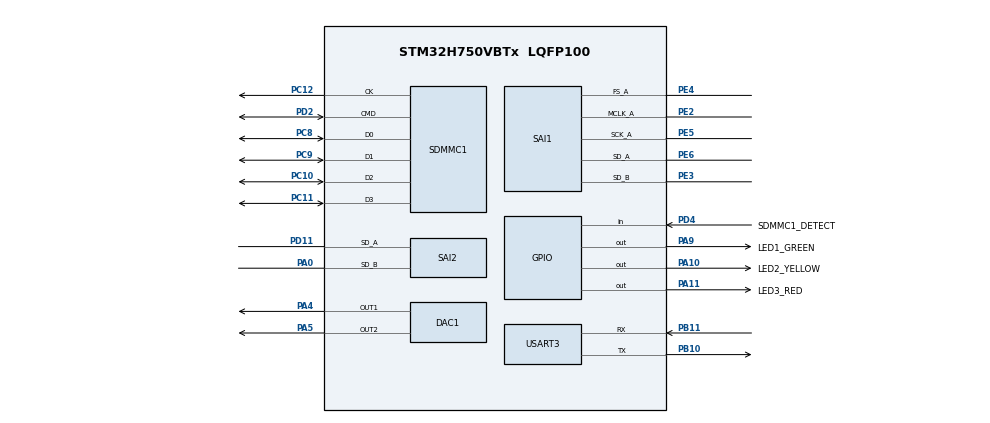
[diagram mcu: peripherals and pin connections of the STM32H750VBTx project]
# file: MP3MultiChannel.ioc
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CORTEX_M7.CPU_DCache=Enabled
CORTEX_M7.CPU_ICache=Enabled
DAC1.DAC1_OutputBuffer-DAC_OUT1=DAC_OUTPUTBUFFER_DISABLE
DAC1.DAC2_OutputBuffer-DAC_OUT2=DAC_OUTPUTBUFFER_DISABLE
DAC1.DAC_Channel-DAC_OUT1=DAC_CHANNEL_1
DAC1.DAC_Channel-DAC_OUT2=DAC_CHANNEL_2
DAC1.DAC_Trigger-DAC_OUT1=DAC_TRIGGER_T6_TRGO
DAC1.DAC_Trigger-DAC_OUT2=DAC_TRIGGER_T6_TRGO
Dma.DAC1_CH1.6.Direction=DMA_MEMORY_TO_PERIPH
Dma.DAC1_CH1.6.EventEnable=DISABLE
Dma.DAC1_CH1.6.FIFOMode=DMA_FIFOMODE_DISABLE
Dma.DAC1_CH1.6.Instance=DMA1_Stream6
Dma.DAC1_CH1.6.MemDataAlignment=DMA_MDATAALIGN_BYTE
Dma.DAC1_CH1.6.MemInc=DMA_MINC_ENABLE
Dma.DAC1_CH1.6.Mode=DMA_NORMAL
Dma.DAC1_CH1.6.PeriphDataAlignment=DMA_PDATAALIGN_BYTE
Dma.DAC1_CH1.6.PeriphInc=DMA_PINC_DISABLE
Dma.DAC1_CH1.6.Polarity=HAL_DMAMUX_REQ_GEN_RISING
Dma.DAC1_CH1.6.Priority=DMA_PRIORITY_LOW
Dma.DAC1_CH1.6.RequestNumber=1
Dma.DAC1_CH1.6.SignalID=NONE
Dma.DAC1_CH1.6.SyncEnable=DISABLE
Dma.DAC1_CH1.6.SyncPolarity=HAL_DMAMUX_SYNC_NO_EVENT
Dma.DAC1_CH1.6.SyncRequestNumber=1
Dma.DAC1_CH1.6.SyncSignalID=NONE
Dma.DAC1_CH2.7.Direction=DMA_MEMORY_TO_PERIPH
Dma.DAC1_CH2.7.EventEnable=DISABLE
Dma.DAC1_CH2.7.FIFOMode=DMA_FIFOMODE_DISABLE
Dma.DAC1_CH2.7.Instance=DMA1_Stream7
Dma.DAC1_CH2.7.MemDataAlignment=DMA_MDATAALIGN_BYTE
Dma.DAC1_CH2.7.MemInc=DMA_MINC_ENABLE
Dma.DAC1_CH2.7.Mode=DMA_NORMAL
Dma.DAC1_CH2.7.PeriphDataAlignment=DMA_PDATAALIGN_BYTE
Dma.DAC1_CH2.7.PeriphInc=DMA_PINC_DISABLE
Dma.DAC1_CH2.7.Polarity=HAL_DMAMUX_REQ_GEN_RISING
Dma.DAC1_CH2.7.Priority=DMA_PRIORITY_LOW
Dma.DAC1_CH2.7.RequestNumber=1
Dma.DAC1_CH2.7.SignalID=NONE
Dma.DAC1_CH2.7.SyncEnable=DISABLE
Dma.DAC1_CH2.7.SyncPolarity=HAL_DMAMUX_SYNC_NO_EVENT
Dma.DAC1_CH2.7.SyncRequestNumber=1
Dma.DAC1_CH2.7.SyncSignalID=NONE
Dma.Request0=SAI1_A
Dma.Request1=SAI1_B
Dma.Request2=SAI2_A
Dma.Request3=SAI2_B
Dma.Request4=USART3_RX
Dma.Request5=USART3_TX
Dma.Request6=DAC1_CH1
Dma.Request7=DAC1_CH2
Dma.SAI1_A.0.Direction=DMA_MEMORY_TO_PERIPH
Dma.SAI1_A.0.EventEnable=DISABLE
Dma.SAI1_A.0.FIFOMode=DMA_FIFOMODE_ENABLE
Dma.SAI1_A.0.FIFOThreshold=DMA_FIFO_THRESHOLD_FULL
Dma.SAI1_A.0.Instance=DMA1_Stream0
Dma.SAI1_A.0.MemBurst=DMA_MBURST_SINGLE
Dma.SAI1_A.0.MemDataAlignment=DMA_MDATAALIGN_HALFWORD
Dma.SAI1_A.0.MemInc=DMA_MINC_ENABLE
Dma.SAI1_A.0.Mode=DMA_CIRCULAR
Dma.SAI1_A.0.PeriphBurst=DMA_PBURST_SINGLE
Dma.SAI1_A.0.PeriphDataAlignment=DMA_PDATAALIGN_HALFWORD
Dma.SAI1_A.0.PeriphInc=DMA_PINC_DISABLE
Dma.SAI1_A.0.Polarity=HAL_DMAMUX_REQ_GEN_RISING
Dma.SAI1_A.0.Priority=DMA_PRIORITY_HIGH
Dma.SAI1_A.0.RequestNumber=1
Dma.SAI1_A.0.SignalID=NONE
Dma.SAI1_A.0.SyncEnable=DISABLE
Dma.SAI1_A.0.SyncPolarity=HAL_DMAMUX_SYNC_NO_EVENT
Dma.SAI1_A.0.SyncRequestNumber=1
Dma.SAI1_A.0.SyncSignalID=NONE
Dma.SAI1_B.1.Direction=DMA_MEMORY_TO_PERIPH
Dma.SAI1_B.1.EventEnable=DISABLE
Dma.SAI1_B.1.FIFOMode=DMA_FIFOMODE_ENABLE
Dma.SAI1_B.1.FIFOThreshold=DMA_FIFO_THRESHOLD_FULL
Dma.SAI1_B.1.Instance=DMA1_Stream1
Dma.SAI1_B.1.MemBurst=DMA_MBURST_SINGLE
Dma.SAI1_B.1.MemDataAlignment=DMA_MDATAALIGN_HALFWORD
Dma.SAI1_B.1.MemInc=DMA_MINC_ENABLE
Dma.SAI1_B.1.Mode=DMA_CIRCULAR
Dma.SAI1_B.1.PeriphBurst=DMA_PBURST_SINGLE
Dma.SAI1_B.1.PeriphDataAlignment=DMA_PDATAALIGN_HALFWORD
Dma.SAI1_B.1.PeriphInc=DMA_PINC_DISABLE
Dma.SAI1_B.1.Polarity=HAL_DMAMUX_REQ_GEN_RISING
Dma.SAI1_B.1.Priority=DMA_PRIORITY_HIGH
Dma.SAI1_B.1.RequestNumber=1
Dma.SAI1_B.1.SignalID=NONE
Dma.SAI1_B.1.SyncEnable=DISABLE
Dma.SAI1_B.1.SyncPolarity=HAL_DMAMUX_SYNC_NO_EVENT
Dma.SAI1_B.1.SyncRequestNumber=1
Dma.SAI1_B.1.SyncSignalID=NONE
Dma.SAI2_A.2.Direction=DMA_MEMORY_TO_PERIPH
Dma.SAI2_A.2.EventEnable=DISABLE
Dma.SAI2_A.2.FIFOMode=DMA_FIFOMODE_ENABLE
Dma.SAI2_A.2.FIFOThreshold=DMA_FIFO_THRESHOLD_FULL
Dma.SAI2_A.2.Instance=DMA1_Stream2
Dma.SAI2_A.2.MemBurst=DMA_MBURST_SINGLE
Dma.SAI2_A.2.MemDataAlignment=DMA_MDATAALIGN_HALFWORD
Dma.SAI2_A.2.MemInc=DMA_MINC_ENABLE
Dma.SAI2_A.2.Mode=DMA_CIRCULAR
Dma.SAI2_A.2.PeriphBurst=DMA_PBURST_SINGLE
Dma.SAI2_A.2.PeriphDataAlignment=DMA_PDATAALIGN_HALFWORD
Dma.SAI2_A.2.PeriphInc=DMA_PINC_DISABLE
Dma.SAI2_A.2.Polarity=HAL_DMAMUX_REQ_GEN_RISING
Dma.SAI2_A.2.Priority=DMA_PRIORITY_HIGH
Dma.SAI2_A.2.RequestNumber=1
Dma.SAI2_A.2.SignalID=NONE
Dma.SAI2_A.2.SyncEnable=DISABLE
Dma.SAI2_A.2.SyncPolarity=HAL_DMAMUX_SYNC_NO_EVENT
Dma.SAI2_A.2.SyncRequestNumber=1
Dma.SAI2_A.2.SyncSignalID=NONE
Dma.SAI2_B.3.Direction=DMA_MEMORY_TO_PERIPH
Dma.SAI2_B.3.EventEnable=DISABLE
Dma.SAI2_B.3.FIFOMode=DMA_FIFOMODE_ENABLE
Dma.SAI2_B.3.FIFOThreshold=DMA_FIFO_THRESHOLD_FULL
Dma.SAI2_B.3.Instance=DMA1_Stream3
Dma.SAI2_B.3.MemBurst=DMA_MBURST_SINGLE
Dma.SAI2_B.3.MemDataAlignment=DMA_MDATAALIGN_HALFWORD
Dma.SAI2_B.3.MemInc=DMA_MINC_ENABLE
Dma.SAI2_B.3.Mode=DMA_CIRCULAR
Dma.SAI2_B.3.PeriphBurst=DMA_PBURST_SINGLE
Dma.SAI2_B.3.PeriphDataAlignment=DMA_PDATAALIGN_HALFWORD
Dma.SAI2_B.3.PeriphInc=DMA_PINC_DISABLE
Dma.SAI2_B.3.Polarity=HAL_DMAMUX_REQ_GEN_RISING
Dma.SAI2_B.3.Priority=DMA_PRIORITY_HIGH
Dma.SAI2_B.3.RequestNumber=1
Dma.SAI2_B.3.SignalID=NONE
Dma.SAI2_B.3.SyncEnable=DISABLE
Dma.SAI2_B.3.SyncPolarity=HAL_DMAMUX_SYNC_NO_EVENT
Dma.SAI2_B.3.SyncRequestNumber=1
Dma.SAI2_B.3.SyncSignalID=NONE
Dma.USART3_RX.4.Direction=DMA_PERIPH_TO_MEMORY
Dma.USART3_RX.4.EventEnable=DISABLE
Dma.USART3_RX.4.FIFOMode=DMA_FIFOMODE_DISABLE
Dma.USART3_RX.4.Instance=DMA1_Stream4
Dma.USART3_RX.4.MemDataAlignment=DMA_MDATAALIGN_BYTE
Dma.USART3_RX.4.MemInc=DMA_MINC_ENABLE
Dma.USART3_RX.4.Mode=DMA_CIRCULAR
Dma.USART3_RX.4.PeriphDataAlignment=DMA_PDATAALIGN_BYTE
Dma.USART3_RX.4.PeriphInc=DMA_PINC_DISABLE
Dma.USART3_RX.4.Polarity=HAL_DMAMUX_REQ_GEN_RISING
Dma.USART3_RX.4.Priority=DMA_PRIORITY_LOW
Dma.USART3_RX.4.RequestNumber=1
Dma.USART3_RX.4.SignalID=NONE
Dma.USART3_RX.4.SyncEnable=DISABLE
Dma.USART3_RX.4.SyncPolarity=HAL_DMAMUX_SYNC_NO_EVENT
Dma.USART3_RX.4.SyncRequestNumber=1
Dma.USART3_RX.4.SyncSignalID=NONE
Dma.USART3_TX.5.Direction=DMA_MEMORY_TO_PERIPH
Dma.USART3_TX.5.EventEnable=DISABLE
Dma.USART3_TX.5.FIFOMode=DMA_FIFOMODE_DISABLE
Dma.USART3_TX.5.Instance=DMA1_Stream5
Dma.USART3_TX.5.MemDataAlignment=DMA_MDATAALIGN_BYTE
Dma.USART3_TX.5.MemInc=DMA_MINC_ENABLE
Dma.USART3_TX.5.Mode=DMA_NORMAL
Dma.USART3_TX.5.PeriphDataAlignment=DMA_PDATAALIGN_BYTE
Dma.USART3_TX.5.PeriphInc=DMA_PINC_DISABLE
Dma.USART3_TX.5.Polarity=HAL_DMAMUX_REQ_GEN_RISING
Dma.USART3_TX.5.Priority=DMA_PRIORITY_LOW
Dma.USART3_TX.5.RequestNumber=1
Dma.USART3_TX.5.SignalID=NONE
Dma.USART3_TX.5.SyncEnable=DISABLE
Dma.USART3_TX.5.SyncPolarity=HAL_DMAMUX_SYNC_NO_EVENT
Dma.USART3_TX.5.SyncRequestNumber=1
Dma.USART3_TX.5.SyncSignalID=NONE
FATFS.BSP.number=1
FATFS._FS_LOCK=48
FATFS._FS_RPATH=2
FATFS._USE_FIND=1
FATFS._USE_LFN=2
FATFS._USE_MUTEX=1
FATFS0.BSP.STBoard=false
FATFS0.BSP.api=Unknown
FATFS0.BSP.instance=PD4
FATFS0.BSP.ip=GPIO
FATFS0.BSP.mode=Input
FATFS0.BSP.name=Detect_SDIO
FATFS0.BSP.solution=PD4
FREERTOS.Tasks01=taskDefault,40,1024,StartDefaultTask,Default,NULL,Static,taskDefaultBuffer,taskDefaultControlBlock
FREERTOS.configENABLE_FPU=1
FREERTOS.configMINIMAL_STACK_SIZE=256
FREERTOS.configTOTAL_HEAP_SIZE=131072
FREERTOS.configUSE_NEWLIB_REENTRANT=1
Mcu.Family=STM32H7
Mcu.Name=STM32H750VBTx
Mcu.Package=LQFP100
NVIC.DMA1_Stream0_IRQn=true\:6\:0\:true\:false\:true\:true\:false\:true\:true
NVIC.DMA1_Stream1_IRQn=true\:7\:0\:true\:false\:true\:true\:false\:true\:true
NVIC.DMA1_Stream2_IRQn=true\:7\:0\:true\:false\:true\:true\:false\:true\:true
NVIC.DMA1_Stream3_IRQn=true\:7\:0\:true\:false\:true\:true\:false\:true\:true
NVIC.DMA1_Stream4_IRQn=true\:15\:0\:true\:false\:true\:true\:false\:true\:true
NVIC.DMA1_Stream5_IRQn=true\:15\:0\:true\:false\:true\:true\:false\:true\:true
NVIC.DMA1_Stream6_IRQn=true\:5\:0\:false\:false\:true\:true\:false\:true\:true
NVIC.DMA1_Stream7_IRQn=true\:5\:0\:false\:false\:true\:true\:false\:true\:true
NVIC.PriorityGroup=NVIC_PRIORITYGROUP_4
NVIC.SAI1_IRQn=true\:12\:0\:true\:false\:true\:true\:true\:true\:true
NVIC.SAI2_IRQn=true\:12\:0\:true\:false\:true\:true\:true\:true\:true
NVIC.SDMMC1_IRQn=true\:7\:0\:true\:false\:true\:true\:true\:true\:true
NVIC.TIM7_IRQn=true\:0\:0\:true\:false\:true\:false\:false\:true\:true
NVIC.TimeBase=TIM7_IRQn
NVIC.TimeBaseIP=TIM7
NVIC.USART3_IRQn=true\:13\:0\:true\:false\:true\:true\:true\:true\:true
PA0.GPIO_Speed=GPIO_SPEED_FREQ_VERY_HIGH
PA0.Mode=SAI_B_SyncSlave
PA0.Signal=SAI2_SD_B
PA10.GPIO_Label=LED2_YELLOW
PA10.Signal=GPIO_Output
PA11.GPIO_Label=LED3_RED
PA11.Signal=GPIO_Output
PA13\ (JTMS/SWDIO).Mode=Trace_Asynchronous_SW
PA13\ (JTMS/SWDIO).Signal=DEBUG_JTMS-SWDIO
PA14\ (JTCK/SWCLK).Mode=Trace_Asynchronous_SW
PA14\ (JTCK/SWCLK).Signal=DEBUG_JTCK-SWCLK
PA4.Signal=COMP_DAC11_group
PA5.Signal=COMP_DAC12_group
PA9.GPIO_Label=LED1_GREEN
PA9.Signal=GPIO_Output
PB10.GPIO_Speed=GPIO_SPEED_FREQ_VERY_HIGH
PB10.Mode=Asynchronous
PB10.Signal=USART3_TX
PB11.GPIO_Speed=GPIO_SPEED_FREQ_VERY_HIGH
PB11.Mode=Asynchronous
PB11.Signal=USART3_RX
PB3\ (JTDO/TRACESWO).Mode=Trace_Asynchronous_SW
PB3\ (JTDO/TRACESWO).Signal=DEBUG_JTDO-SWO
PC10.GPIO_PuPd=GPIO_PULLUP
PC10.Mode=SD_4_bits_Wide_bus
PC10.Signal=SDMMC1_D2
PC11.GPIO_PuPd=GPIO_PULLUP
PC11.Mode=SD_4_bits_Wide_bus
PC11.Signal=SDMMC1_D3
PC12.GPIO_PuPd=GPIO_PULLUP
PC12.Mode=SD_4_bits_Wide_bus
PC12.Signal=SDMMC1_CK
PC8.GPIO_PuPd=GPIO_PULLUP
PC8.Mode=SD_4_bits_Wide_bus
PC8.Signal=SDMMC1_D0
PC9.GPIO_PuPd=GPIO_PULLUP
PC9.Mode=SD_4_bits_Wide_bus
PC9.Signal=SDMMC1_D1
PD11.GPIO_Speed=GPIO_SPEED_FREQ_VERY_HIGH
PD11.Mode=SAI_A_SyncSlave
PD11.Signal=SAI2_SD_A
PD2.GPIO_PuPd=GPIO_PULLUP
PD2.Mode=SD_4_bits_Wide_bus
PD2.Signal=SDMMC1_CMD
PD4.GPIO_Label=SDMMC1_DETECT
PD4.GPIO_PuPd=GPIO_PULLUP
PD4.Signal=GPIO_Input
PE2.GPIO_Speed=GPIO_SPEED_FREQ_VERY_HIGH
PE2.Mode=SAI_A_MasterWithClock
PE2.Signal=SAI1_MCLK_A
PE3.GPIO_Speed=GPIO_SPEED_FREQ_VERY_HIGH
PE3.Mode=SAI_B_SyncSlave
PE3.Signal=SAI1_SD_B
PE4.GPIO_Speed=GPIO_SPEED_FREQ_VERY_HIGH
PE4.Mode=SAI_A_MasterWithClock
PE4.Signal=SAI1_FS_A
PE5.GPIO_Speed=GPIO_SPEED_FREQ_VERY_HIGH
PE5.Mode=SAI_A_MasterWithClock
PE5.Signal=SAI1_SCK_A
PE6.GPIO_Speed=GPIO_SPEED_FREQ_VERY_HIGH
PE6.Mode=SAI_A_MasterWithClock
PE6.Signal=SAI1_SD_A
PH0-OSC_IN\ (PH0).Mode=HSE-External-Oscillator
PH0-OSC_IN\ (PH0).Signal=RCC_OSC_IN
PH1-OSC_OUT\ (PH1).Mode=HSE-External-Oscillator
PH1-OSC_OUT\ (PH1).Signal=RCC_OSC_OUT
ProjectManager.HeapSize=0x200
ProjectManager.StackSize=0x400
ProjectManager.TargetToolchain=STM32CubeIDE
RCC.ADCFreq_Value=22222222.222222224
RCC.APB1Freq_Value=120000000
RCC.APB2Freq_Value=120000000
RCC.APB3Freq_Value=120000000
RCC.APB4Freq_Value=120000000
RCC.CortexFreq_Value=480000000
RCC.D1PPRE=RCC_APB3_DIV2
RCC.D2PPRE1=RCC_APB1_DIV2
RCC.D2PPRE2=RCC_APB2_DIV2
RCC.D3PPRE=RCC_APB4_DIV2
RCC.DIVM1=5
RCC.DIVM2=7
RCC.DIVN1=192
RCC.DIVN2=56
RCC.DIVP2=9
RCC.EnbaleCSS=true
RCC.HCLKFreq_Value=240000000
RCC.HPRE=RCC_HCLK_DIV2
RCC.LockedElements=D1CPREOutput,AHBOutput,SAI1output,SAI23output
RCC.PLL2FRACN=0
RCC.PLL3FRACN=0
RCC.PLLFRACN=0
RCC.PLLSourceVirtual=RCC_PLLSOURCE_HSE
RCC.SAI1CLockSelection=RCC_SAI1CLKSOURCE_PLL2
RCC.SAI23CLockSelection=RCC_SAI23CLKSOURCE_PLL2
RCC.SDMMC1CLockSelection=RCC_SDMMCCLKSOURCE_PLL2
RCC.SYSCLKFreq_VALUE=480000000
RCC.SYSCLKSource=RCC_SYSCLKSOURCE_PLLCLK
RCC.SupplySource=PWR_LDO_SUPPLY
RCC.USBFreq_Value=480000000
SAI1.AudioFrequency-SAI_A_MasterWithClock=SAI_AUDIO_FREQUENCY_44K
SAI1.AudioMode-SAI_B_SyncSlave=SAI_MODESLAVE_TX
SAI1.ClockStrobing-SAI_A_MasterWithClock=SAI_CLOCKSTROBING_RISINGEDGE
SAI1.ClockStrobing-SAI_B_SyncSlave=SAI_CLOCKSTROBING_RISINGEDGE
SAI1.DataSize-SAI_A_MasterWithClock=SAI_DATASIZE_16
SAI1.DataSize-SAI_B_SyncSlave=SAI_DATASIZE_16
SAI1.ErrorAudioFreq-SAI_A_MasterWithClock=-1.35 %
SAI1.FSOffset-SAI_A_MasterWithClock=SAI_FS_BEFOREFIRSTBIT
SAI1.FSPolarity-SAI_A_MasterWithClock=SAI_FS_ACTIVE_HIGH
SAI1.FrameLength-SAI_A_MasterWithClock=256
SAI1.FrameLength-SAI_B_SyncSlave=256
SAI1.Instance-SAI_A_MasterWithClock=SAI$Index_Block_A
SAI1.Instance-SAI_B_SyncSlave=SAI$Index_Block_B
SAI1.MClockEnable=SAI_MASTERCLOCK_ENABLE
SAI1.RealAudioFreq-SAI_A_MasterWithClock=43.402 KHz
SAI1.SlotActive-SAI_A_MasterWithClock=0x0000FFFF
SAI1.SlotActive-SAI_B_SyncSlave=0x0000FFFF
SAI1.SlotNumber-SAI_A_MasterWithClock=16
SAI1.SlotNumber-SAI_B_SyncSlave=16
SAI1.SynchroExt=SAI_SYNCEXT_OUTBLOCKA_ENABLE
SAI1.VirtualMode-SAI_A_MasterWithClock=VM_MASTER
SAI1.VirtualMode-SAI_B_SyncSlave=VM_SLAVE
SAI1.VirtualSlotActive-SAI_A_MasterWithClock=SAI_SLOTACTIVE_ALL
SAI1.VirtualSlotActive-SAI_B_SyncSlave=SAI_SLOTACTIVE_ALL
SAI2.AudioMode-SAI_A_SyncSlave=SAI_MODESLAVE_TX
SAI2.AudioMode-SAI_B_SyncSlave=SAI_MODESLAVE_TX
SAI2.ClockStrobing-SAI_A_SyncSlave=SAI_CLOCKSTROBING_RISINGEDGE
SAI2.ClockStrobing-SAI_B_SyncSlave=SAI_CLOCKSTROBING_RISINGEDGE
SAI2.DataSize-SAI_A_SyncSlave=SAI_DATASIZE_16
SAI2.DataSize-SAI_B_SyncSlave=SAI_DATASIZE_16
SAI2.FSOffset-SAI_A_SyncSlave=SAI_FS_BEFOREFIRSTBIT
SAI2.FSPolarity-SAI_A_SyncSlave=SAI_FS_ACTIVE_HIGH
SAI2.FrameLength-SAI_A_SyncSlave=256
SAI2.FrameLength-SAI_B_SyncSlave=256
SAI2.Instance-SAI_A_SyncSlave=SAI$Index_Block_A
SAI2.Instance-SAI_B_SyncSlave=SAI$Index_Block_B
SAI2.SlotActive-SAI_A_SyncSlave=0x0000FFFF
SAI2.SlotActive-SAI_B_SyncSlave=0x0000FFFF
SAI2.SlotNumber-SAI_A_SyncSlave=16
SAI2.SlotNumber-SAI_B_SyncSlave=16
SAI2.Synchro_A=SAI_SYNCHRONOUS_EXT_SAI1
SAI2.Synchro_B=SAI_SYNCHRONOUS_EXT_SAI1
SAI2.VirtualMode-SAI_A_SyncSlave=VM_SLAVE
SAI2.VirtualMode-SAI_B_SyncSlave=VM_SLAVE
SAI2.VirtualSlotActive-SAI_A_SyncSlave=SAI_SLOTACTIVE_ALL
SAI2.VirtualSlotActive-SAI_B_SyncSlave=SAI_SLOTACTIVE_ALL
SDMMC1.ClockDiv=2
SH.COMP_DAC11_group.0=DAC1_OUT1,DAC_OUT1
SH.COMP_DAC12_group.0=DAC1_OUT2,DAC_OUT2
TIM5.Period=0xffffffff
TIM5.Prescaler=280-1
USART3.VirtualMode-Asynchronous=VM_ASYNC
VP_FATFS_VS_SDIO.Mode=SDIO
VP_FREERTOS_VS_CMSIS_V2.Mode=CMSIS_V2
VP_SAI1_VP_$IpInstance_SYNCHRO_EXTERNAL.Mode=SynchroExternal
VP_SYS_VS_tim7.Mode=TIM7
VP_TIM5_VS_ClockSourceINT.Mode=Internal
VP_TIM6_VS_ClockSourceINT.Mode=Enable_Timer
board=custom

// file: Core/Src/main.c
/* USER CODE BEGIN Header */
/**
  ******************************************************************************
  * @file           : main.c
  * @brief          : Main program body
  ******************************************************************************
  * @attention
  *
  * Copyright (c) 2022 STMicroelectronics.
  * All rights reserved.
  *
  * This software is licensed under terms that can be found in the LICENSE file
  * in the root directory of this software component.
  * If no LICENSE file comes with this software, it is provided AS-IS.
  *
  ******************************************************************************
  */
/* USER CODE END Header */
#include "main.h"
#include "cmsis_os.h"
#include "fatfs.h"

/* USER CODE BEGIN Includes */
#include "player.h"
/* USER CODE END Includes */

typedef StaticTask_t osStaticThreadDef_t;

DAC_HandleTypeDef hdac1;
DMA_HandleTypeDef hdma_dac1_ch1;
DMA_HandleTypeDef hdma_dac1_ch2;

SAI_HandleTypeDef hsai_BlockA1;
SAI_HandleTypeDef hsai_BlockB1;
SAI_HandleTypeDef hsai_BlockA2;
SAI_HandleTypeDef hsai_BlockB2;
DMA_HandleTypeDef hdma_sai1_a;
DMA_HandleTypeDef hdma_sai1_b;
DMA_HandleTypeDef hdma_sai2_a;
DMA_HandleTypeDef hdma_sai2_b;

SD_HandleTypeDef hsd1;

TIM_HandleTypeDef htim5;
TIM_HandleTypeDef htim6;

UART_HandleTypeDef huart3;
DMA_HandleTypeDef hdma_usart3_rx;
DMA_HandleTypeDef hdma_usart3_tx;

/* Definitions for taskDefault */
osThreadId_t taskDefaultHandle;
const osThreadAttr_t taskDefault_attributes = {
  .name = "taskDefault",
  .stack_size = 1024 * 4,
  .priority = (osPriority_t) osPriorityHigh,
};

void SystemClock_Config(void);
void PeriphCommonClock_Config(void);
static void MX_GPIO_Init(void);
static void MX_DMA_Init(void);
static void MX_SDMMC1_SD_Init(void);
static void MX_SAI1_Init(void);
static void MX_SAI2_Init(void);
static void MX_USART3_UART_Init(void);
static void MX_TIM5_Init(void);
static void MX_DAC1_Init(void);
static void MX_TIM6_Init(void);
void StartDefaultTask(void *argument);

int main(void)
{

  /* Enable I-Cache---------------------------------------------------------*/
  SCB_EnableICache();

  /* Enable D-Cache---------------------------------------------------------*/
  SCB_EnableDCache();

  /* MCU Configuration--------------------------------------------------------*/

  /* Reset of all peripherals, Initializes the Flash interface and the Systick. */
  HAL_Init();

  /* Configure the system clock */
  SystemClock_Config();

/* Configure the peripherals common clocks */
  PeriphCommonClock_Config();

  /* USER CODE BEGIN SysInit */
  MX_DMA_Init();

  /* USER CODE END SysInit */

  /* Initialize all configured peripherals */
  MX_GPIO_Init();
  MX_DMA_Init();
  MX_SDMMC1_SD_Init();
  MX_FATFS_Init();
  MX_SAI1_Init();
  MX_SAI2_Init();
  MX_USART3_UART_Init();
  MX_TIM5_Init();
  MX_DAC1_Init();
  MX_TIM6_Init();

  /* Init scheduler */
  osKernelInitialize();

  /* Create the thread(s) */
  /* creation of taskDefault */
  taskDefaultHandle = osThreadNew(StartDefaultTask, NULL, &taskDefault_attributes);

  /* Start scheduler */
  osKernelStart();
  /* We should never get here as control is now taken by the scheduler */
  /* Infinite loop */
  while (1)
  {

  }
}

void SystemClock_Config(void)
{
  RCC_OscInitTypeDef RCC_OscInitStruct = {0};
  RCC_ClkInitTypeDef RCC_ClkInitStruct = {0};

  /** Supply configuration update enable
  */
  HAL_PWREx_ConfigSupply(PWR_LDO_SUPPLY);

  /** Configure the main internal regulator output voltage
  */
  __HAL_PWR_VOLTAGESCALING_CONFIG(PWR_REGULATOR_VOLTAGE_SCALE1);

  while(!__HAL_PWR_GET_FLAG(PWR_FLAG_VOSRDY)) {}

  __HAL_RCC_SYSCFG_CLK_ENABLE();
  __HAL_PWR_VOLTAGESCALING_CONFIG(PWR_REGULATOR_VOLTAGE_SCALE0);

  while(!__HAL_PWR_GET_FLAG(PWR_FLAG_VOSRDY)) {}

  /** Macro to configure the PLL clock source
  */
  __HAL_RCC_PLL_PLLSOURCE_CONFIG(RCC_PLLSOURCE_HSE);

  /** Initializes the RCC Oscillators according to the specified parameters
  * in the RCC_OscInitTypeDef structure.
  */
  RCC_OscInitStruct.OscillatorType = RCC_OSCILLATORTYPE_HSE;
  RCC_OscInitStruct.HSEState = RCC_HSE_ON;
  RCC_OscInitStruct.PLL.PLLState = RCC_PLL_ON;
  RCC_OscInitStruct.PLL.PLLSource = RCC_PLLSOURCE_HSE;
  RCC_OscInitStruct.PLL.PLLM = 5;
  RCC_OscInitStruct.PLL.PLLN = 192;
  RCC_OscInitStruct.PLL.PLLP = 2;
  RCC_OscInitStruct.PLL.PLLQ = 2;
  RCC_OscInitStruct.PLL.PLLR = 2;
  RCC_OscInitStruct.PLL.PLLRGE = RCC_PLL1VCIRANGE_2;
  RCC_OscInitStruct.PLL.PLLVCOSEL = RCC_PLL1VCOWIDE;
  RCC_OscInitStruct.PLL.PLLFRACN = 0;
  if (HAL_RCC_OscConfig(&RCC_OscInitStruct) != HAL_OK)
  {
    Error_Handler();
  }

  /** Initializes the CPU, AHB and APB buses clocks
  */
  RCC_ClkInitStruct.ClockType = RCC_CLOCKTYPE_HCLK|RCC_CLOCKTYPE_SYSCLK
                              |RCC_CLOCKTYPE_PCLK1|RCC_CLOCKTYPE_PCLK2
                              |RCC_CLOCKTYPE_D3PCLK1|RCC_CLOCKTYPE_D1PCLK1;
  RCC_ClkInitStruct.SYSCLKSource = RCC_SYSCLKSOURCE_PLLCLK;
  RCC_ClkInitStruct.SYSCLKDivider = RCC_SYSCLK_DIV1;
  RCC_ClkInitStruct.AHBCLKDivider = RCC_HCLK_DIV2;
  RCC_ClkInitStruct.APB3CLKDivider = RCC_APB3_DIV2;
  RCC_ClkInitStruct.APB1CLKDivider = RCC_APB1_DIV2;
  RCC_ClkInitStruct.APB2CLKDivider = RCC_APB2_DIV2;
  RCC_ClkInitStruct.APB4CLKDivider = RCC_APB4_DIV2;

  if (HAL_RCC_ClockConfig(&RCC_ClkInitStruct, FLASH_LATENCY_4) != HAL_OK)
  {
    Error_Handler();
  }

  /** Enables the Clock Security System
  */
  HAL_RCC_EnableCSS();
}

void PeriphCommonClock_Config(void)
{
  RCC_PeriphCLKInitTypeDef PeriphClkInitStruct = {0};

  /** Initializes the peripherals clock
  */
  PeriphClkInitStruct.PeriphClockSelection = RCC_PERIPHCLK_SDMMC|RCC_PERIPHCLK_SAI1
                              |RCC_PERIPHCLK_SAI2;
  PeriphClkInitStruct.PLL2.PLL2M = 2;
  PeriphClkInitStruct.PLL2.PLL2N = 56;
  PeriphClkInitStruct.PLL2.PLL2P = 31;
  PeriphClkInitStruct.PLL2.PLL2Q = 7;
  PeriphClkInitStruct.PLL2.PLL2R = 7;
  PeriphClkInitStruct.PLL2.PLL2RGE = RCC_PLL2VCIRANGE_1;
  PeriphClkInitStruct.PLL2.PLL2VCOSEL = RCC_PLL2VCOWIDE;
  PeriphClkInitStruct.PLL2.PLL2FRACN = 0;
  PeriphClkInitStruct.SdmmcClockSelection = RCC_SDMMCCLKSOURCE_PLL2;
  PeriphClkInitStruct.Sai1ClockSelection = RCC_SAI1CLKSOURCE_PLL2;
  PeriphClkInitStruct.Sai23ClockSelection = RCC_SAI23CLKSOURCE_PLL2;
  if (HAL_RCCEx_PeriphCLKConfig(&PeriphClkInitStruct) != HAL_OK)
  {
    Error_Handler();
  }
}

static void MX_DAC1_Init(void)
{

  DAC_ChannelConfTypeDef sConfig = {0};

  /** DAC Initialization
  */
  hdac1.Instance = DAC1;
  if (HAL_DAC_Init(&hdac1) != HAL_OK)
  {
    Error_Handler();
  }

  /** DAC channel OUT1 config
  */
  sConfig.DAC_SampleAndHold = DAC_SAMPLEANDHOLD_DISABLE;
  sConfig.DAC_Trigger = DAC_TRIGGER_T6_TRGO;
  sConfig.DAC_OutputBuffer = DAC_OUTPUTBUFFER_DISABLE;
  sConfig.DAC_ConnectOnChipPeripheral = DAC_CHIPCONNECT_DISABLE;
  sConfig.DAC_UserTrimming = DAC_TRIMMING_FACTORY;
  if (HAL_DAC_ConfigChannel(&hdac1, &sConfig, DAC_CHANNEL_1) != HAL_OK)
  {
    Error_Handler();
  }

  /** DAC channel OUT2 config
  */
  if (HAL_DAC_ConfigChannel(&hdac1, &sConfig, DAC_CHANNEL_2) != HAL_OK)
  {
    Error_Handler();
  }

}

static void MX_SAI1_Init(void)
{

  hsai_BlockA1.Instance = SAI1_Block_A;
  hsai_BlockA1.Init.Protocol = SAI_FREE_PROTOCOL;
  hsai_BlockA1.Init.AudioMode = SAI_MODEMASTER_TX;
  hsai_BlockA1.Init.DataSize = SAI_DATASIZE_16;
  hsai_BlockA1.Init.FirstBit = SAI_FIRSTBIT_MSB;
  hsai_BlockA1.Init.ClockStrobing = SAI_CLOCKSTROBING_FALLINGEDGE;
  hsai_BlockA1.Init.Synchro = SAI_ASYNCHRONOUS;
  hsai_BlockA1.Init.OutputDrive = SAI_OUTPUTDRIVE_DISABLE;
  hsai_BlockA1.Init.NoDivider = SAI_MASTERDIVIDER_ENABLE;
  hsai_BlockA1.Init.FIFOThreshold = SAI_FIFOTHRESHOLD_EMPTY;
  hsai_BlockA1.Init.AudioFrequency = SAI_AUDIO_FREQUENCY_44K;
  hsai_BlockA1.Init.SynchroExt = SAI_SYNCEXT_OUTBLOCKA_ENABLE;
  hsai_BlockA1.Init.MonoStereoMode = SAI_STEREOMODE;
  hsai_BlockA1.Init.CompandingMode = SAI_NOCOMPANDING;
  hsai_BlockA1.Init.TriState = SAI_OUTPUT_NOTRELEASED;
  hsai_BlockA1.Init.PdmInit.Activation = DISABLE;
  hsai_BlockA1.Init.PdmInit.MicPairsNbr = 1;
  hsai_BlockA1.Init.PdmInit.ClockEnable = SAI_PDM_CLOCK1_ENABLE;
  hsai_BlockA1.FrameInit.FrameLength = 256;
  hsai_BlockA1.FrameInit.ActiveFrameLength = 1;
  hsai_BlockA1.FrameInit.FSDefinition = SAI_FS_STARTFRAME;
  hsai_BlockA1.FrameInit.FSPolarity = SAI_FS_ACTIVE_HIGH;
  hsai_BlockA1.FrameInit.FSOffset = SAI_FS_BEFOREFIRSTBIT;
  hsai_BlockA1.SlotInit.FirstBitOffset = 1;
  hsai_BlockA1.SlotInit.SlotSize = SAI_SLOTSIZE_DATASIZE;
  hsai_BlockA1.SlotInit.SlotNumber = 16;
  hsai_BlockA1.SlotInit.SlotActive = 0x0000FFFF;
  if (HAL_SAI_Init(&hsai_BlockA1) != HAL_OK)
  {
    Error_Handler();
  }
  hsai_BlockB1.Instance = SAI1_Block_B;
  hsai_BlockB1.Init.Protocol = SAI_FREE_PROTOCOL;
  hsai_BlockB1.Init.AudioMode = SAI_MODESLAVE_TX;
  hsai_BlockB1.Init.DataSize = SAI_DATASIZE_16;
  hsai_BlockB1.Init.FirstBit = SAI_FIRSTBIT_MSB;
  hsai_BlockB1.Init.ClockStrobing = SAI_CLOCKSTROBING_FALLINGEDGE;
  hsai_BlockB1.Init.Synchro = SAI_SYNCHRONOUS;
  hsai_BlockB1.Init.OutputDrive = SAI_OUTPUTDRIVE_DISABLE;
  hsai_BlockB1.Init.FIFOThreshold = SAI_FIFOTHRESHOLD_EMPTY;
  hsai_BlockB1.Init.SynchroExt = SAI_SYNCEXT_OUTBLOCKA_ENABLE;
  hsai_BlockB1.Init.MonoStereoMode = SAI_STEREOMODE;
  hsai_BlockB1.Init.CompandingMode = SAI_NOCOMPANDING;
  hsai_BlockB1.Init.TriState = SAI_OUTPUT_NOTRELEASED;
  hsai_BlockB1.Init.PdmInit.Activation = DISABLE;
  hsai_BlockB1.Init.PdmInit.MicPairsNbr = 1;
  hsai_BlockB1.Init.PdmInit.ClockEnable = SAI_PDM_CLOCK1_ENABLE;
  hsai_BlockB1.FrameInit.FrameLength = 256;
  hsai_BlockB1.FrameInit.ActiveFrameLength = 1;
  hsai_BlockB1.FrameInit.FSDefinition = SAI_FS_STARTFRAME;
  hsai_BlockB1.FrameInit.FSPolarity = SAI_FS_ACTIVE_LOW;
  hsai_BlockB1.FrameInit.FSOffset = SAI_FS_FIRSTBIT;
  hsai_BlockB1.SlotInit.FirstBitOffset = 1;
  hsai_BlockB1.SlotInit.SlotSize = SAI_SLOTSIZE_DATASIZE;
  hsai_BlockB1.SlotInit.SlotNumber = 16;
  hsai_BlockB1.SlotInit.SlotActive = 0x0000FFFF;
  if (HAL_SAI_Init(&hsai_BlockB1) != HAL_OK)
  {
    Error_Handler();
  }

}

static void MX_SAI2_Init(void)
{

  hsai_BlockA2.Instance = SAI2_Block_A;
  hsai_BlockA2.Init.Protocol = SAI_FREE_PROTOCOL;
  hsai_BlockA2.Init.AudioMode = SAI_MODESLAVE_TX;
  hsai_BlockA2.Init.DataSize = SAI_DATASIZE_16;
  hsai_BlockA2.Init.FirstBit = SAI_FIRSTBIT_MSB;
  hsai_BlockA2.Init.ClockStrobing = SAI_CLOCKSTROBING_FALLINGEDGE;
  hsai_BlockA2.Init.Synchro = SAI_SYNCHRONOUS_EXT_SAI1;
  hsai_BlockA2.Init.OutputDrive = SAI_OUTPUTDRIVE_DISABLE;
  hsai_BlockA2.Init.FIFOThreshold = SAI_FIFOTHRESHOLD_EMPTY;
  hsai_BlockA2.Init.MonoStereoMode = SAI_STEREOMODE;
  hsai_BlockA2.Init.CompandingMode = SAI_NOCOMPANDING;
  hsai_BlockA2.Init.TriState = SAI_OUTPUT_NOTRELEASED;
  hsai_BlockA2.Init.PdmInit.Activation = DISABLE;
  hsai_BlockA2.Init.PdmInit.MicPairsNbr = 1;
  hsai_BlockA2.Init.PdmInit.ClockEnable = SAI_PDM_CLOCK1_ENABLE;
  hsai_BlockA2.FrameInit.FrameLength = 256;
  hsai_BlockA2.FrameInit.ActiveFrameLength = 1;
  hsai_BlockA2.FrameInit.FSDefinition = SAI_FS_STARTFRAME;
  hsai_BlockA2.FrameInit.FSPolarity = SAI_FS_ACTIVE_HIGH;
  hsai_BlockA2.FrameInit.FSOffset = SAI_FS_BEFOREFIRSTBIT;
  hsai_BlockA2.SlotInit.FirstBitOffset = 1;
  hsai_BlockA2.SlotInit.SlotSize = SAI_SLOTSIZE_DATASIZE;
  hsai_BlockA2.SlotInit.SlotNumber = 16;
  hsai_BlockA2.SlotInit.SlotActive = 0x0000FFFF;
  if (HAL_SAI_Init(&hsai_BlockA2) != HAL_OK)
  {
    Error_Handler();
  }
  hsai_BlockB2.Instance = SAI2_Block_B;
  hsai_BlockB2.Init.Protocol = SAI_FREE_PROTOCOL;
  hsai_BlockB2.Init.AudioMode = SAI_MODESLAVE_TX;
  hsai_BlockB2.Init.DataSize = SAI_DATASIZE_16;
  hsai_BlockB2.Init.FirstBit = SAI_FIRSTBIT_MSB;
  hsai_BlockB2.Init.ClockStrobing = SAI_CLOCKSTROBING_FALLINGEDGE;
  hsai_BlockB2.Init.Synchro = SAI_SYNCHRONOUS_EXT_SAI1;
  hsai_BlockB2.Init.OutputDrive = SAI_OUTPUTDRIVE_DISABLE;
  hsai_BlockB2.Init.FIFOThreshold = SAI_FIFOTHRESHOLD_EMPTY;
  hsai_BlockB2.Init.MonoStereoMode = SAI_STEREOMODE;
  hsai_BlockB2.Init.CompandingMode = SAI_NOCOMPANDING;
  hsai_BlockB2.Init.TriState = SAI_OUTPUT_NOTRELEASED;
  hsai_BlockB2.Init.PdmInit.Activation = DISABLE;
  hsai_BlockB2.Init.PdmInit.MicPairsNbr = 1;
  hsai_BlockB2.Init.PdmInit.ClockEnable = SAI_PDM_CLOCK1_ENABLE;
  hsai_BlockB2.FrameInit.FrameLength = 256;
  hsai_BlockB2.FrameInit.ActiveFrameLength = 1;
  hsai_BlockB2.FrameInit.FSDefinition = SAI_FS_STARTFRAME;
  hsai_BlockB2.FrameInit.FSPolarity = SAI_FS_ACTIVE_LOW;
  hsai_BlockB2.FrameInit.FSOffset = SAI_FS_FIRSTBIT;
  hsai_BlockB2.SlotInit.FirstBitOffset = 1;
  hsai_BlockB2.SlotInit.SlotSize = SAI_SLOTSIZE_DATASIZE;
  hsai_BlockB2.SlotInit.SlotNumber = 16;
  hsai_BlockB2.SlotInit.SlotActive = 0x0000FFFF;
  if (HAL_SAI_Init(&hsai_BlockB2) != HAL_OK)
  {
    Error_Handler();
  }

}

static void MX_SDMMC1_SD_Init(void)
{

  hsd1.Instance = SDMMC1;
  hsd1.Init.ClockEdge = SDMMC_CLOCK_EDGE_RISING;
  hsd1.Init.ClockPowerSave = SDMMC_CLOCK_POWER_SAVE_DISABLE;
  hsd1.Init.BusWide = SDMMC_BUS_WIDE_4B;
  hsd1.Init.HardwareFlowControl = SDMMC_HARDWARE_FLOW_CONTROL_DISABLE;
  hsd1.Init.ClockDiv = 0;

}

static void MX_TIM5_Init(void)
{

  TIM_ClockConfigTypeDef sClockSourceConfig = {0};
  TIM_MasterConfigTypeDef sMasterConfig = {0};

  htim5.Instance = TIM5;
  htim5.Init.Prescaler = 120-1;
  htim5.Init.CounterMode = TIM_COUNTERMODE_UP;
  htim5.Init.Period = 0xffffffff;
  htim5.Init.ClockDivision = TIM_CLOCKDIVISION_DIV1;
  htim5.Init.AutoReloadPreload = TIM_AUTORELOAD_PRELOAD_DISABLE;
  if (HAL_TIM_Base_Init(&htim5) != HAL_OK)
  {
    Error_Handler();
  }
  sClockSourceConfig.ClockSource = TIM_CLOCKSOURCE_INTERNAL;
  if (HAL_TIM_ConfigClockSource(&htim5, &sClockSourceConfig) != HAL_OK)
  {
    Error_Handler();
  }
  sMasterConfig.MasterOutputTrigger = TIM_TRGO_RESET;
  sMasterConfig.MasterSlaveMode = TIM_MASTERSLAVEMODE_DISABLE;
  if (HAL_TIMEx_MasterConfigSynchronization(&htim5, &sMasterConfig) != HAL_OK)
  {
    Error_Handler();
  }

}

static void MX_TIM6_Init(void)
{

  TIM_MasterConfigTypeDef sMasterConfig = {0};

  htim6.Instance = TIM6;
  htim6.Init.Prescaler = 0;
  htim6.Init.CounterMode = TIM_COUNTERMODE_UP;
  htim6.Init.Period = 2721 - 1;
  htim6.Init.AutoReloadPreload = TIM_AUTORELOAD_PRELOAD_DISABLE;
  if (HAL_TIM_Base_Init(&htim6) != HAL_OK)
  {
    Error_Handler();
  }
  sMasterConfig.MasterOutputTrigger = TIM_TRGO_UPDATE;
  sMasterConfig.MasterSlaveMode = TIM_MASTERSLAVEMODE_DISABLE;
  if (HAL_TIMEx_MasterConfigSynchronization(&htim6, &sMasterConfig) != HAL_OK)
  {
    Error_Handler();
  }

}

static void MX_USART3_UART_Init(void)
{

  huart3.Instance = USART3;
  huart3.Init.BaudRate = 115200;
  huart3.Init.WordLength = UART_WORDLENGTH_8B;
  huart3.Init.StopBits = UART_STOPBITS_1;
  huart3.Init.Parity = UART_PARITY_NONE;
  huart3.Init.Mode = UART_MODE_TX_RX;
  huart3.Init.HwFlowCtl = UART_HWCONTROL_NONE;
  huart3.Init.OverSampling = UART_OVERSAMPLING_16;
  huart3.Init.OneBitSampling = UART_ONE_BIT_SAMPLE_DISABLE;
  huart3.Init.ClockPrescaler = UART_PRESCALER_DIV1;
  huart3.AdvancedInit.AdvFeatureInit = UART_ADVFEATURE_NO_INIT;
  if (HAL_UART_Init(&huart3) != HAL_OK)
  {
    Error_Handler();
  }
  if (HAL_UARTEx_SetTxFifoThreshold(&huart3, UART_TXFIFO_THRESHOLD_1_8) != HAL_OK)
  {
    Error_Handler();
  }
  if (HAL_UARTEx_SetRxFifoThreshold(&huart3, UART_RXFIFO_THRESHOLD_1_8) != HAL_OK)
  {
    Error_Handler();
  }
  if (HAL_UARTEx_DisableFifoMode(&huart3) != HAL_OK)
  {
    Error_Handler();
  }

}

static void MX_DMA_Init(void)
{

  /* DMA controller clock enable */
  __HAL_RCC_DMA1_CLK_ENABLE();

  /* DMA interrupt init */
  /* DMA1_Stream0_IRQn interrupt configuration */
  HAL_NVIC_SetPriority(DMA1_Stream0_IRQn, 6, 0);
  HAL_NVIC_EnableIRQ(DMA1_Stream0_IRQn);
  /* DMA1_Stream1_IRQn interrupt configuration */
  HAL_NVIC_SetPriority(DMA1_Stream1_IRQn, 7, 0);
  HAL_NVIC_EnableIRQ(DMA1_Stream1_IRQn);
  /* DMA1_Stream2_IRQn interrupt configuration */
  HAL_NVIC_SetPriority(DMA1_Stream2_IRQn, 7, 0);
  HAL_NVIC_EnableIRQ(DMA1_Stream2_IRQn);
  /* DMA1_Stream3_IRQn interrupt configuration */
  HAL_NVIC_SetPriority(DMA1_Stream3_IRQn, 7, 0);
  HAL_NVIC_EnableIRQ(DMA1_Stream3_IRQn);
  /* DMA1_Stream4_IRQn interrupt configuration */
  HAL_NVIC_SetPriority(DMA1_Stream4_IRQn, 15, 0);
  HAL_NVIC_EnableIRQ(DMA1_Stream4_IRQn);
  /* DMA1_Stream5_IRQn interrupt configuration */
  HAL_NVIC_SetPriority(DMA1_Stream5_IRQn, 15, 0);
  HAL_NVIC_EnableIRQ(DMA1_Stream5_IRQn);
  /* DMA1_Stream6_IRQn interrupt configuration */
  HAL_NVIC_SetPriority(DMA1_Stream6_IRQn, 8, 0);
  HAL_NVIC_EnableIRQ(DMA1_Stream6_IRQn);
  /* DMA1_Stream7_IRQn interrupt configuration */
  HAL_NVIC_SetPriority(DMA1_Stream7_IRQn, 8, 0);
  HAL_NVIC_EnableIRQ(DMA1_Stream7_IRQn);

}

static void MX_GPIO_Init(void)
{
  GPIO_InitTypeDef GPIO_InitStruct = {0};

  /* GPIO Ports Clock Enable */
  __HAL_RCC_GPIOE_CLK_ENABLE();
  __HAL_RCC_GPIOH_CLK_ENABLE();
  __HAL_RCC_GPIOA_CLK_ENABLE();
  __HAL_RCC_GPIOB_CLK_ENABLE();
  __HAL_RCC_GPIOD_CLK_ENABLE();
  __HAL_RCC_GPIOC_CLK_ENABLE();

  /*Configure GPIO pin Output Level */
  HAL_GPIO_WritePin(GPIOA, LED1_GREEN_Pin|LED2_YELLOW_Pin|LED3_RED_Pin, GPIO_PIN_RESET);

  /*Configure GPIO pins : LED1_GREEN_Pin LED2_YELLOW_Pin LED3_RED_Pin */
  GPIO_InitStruct.Pin = LED1_GREEN_Pin|LED2_YELLOW_Pin|LED3_RED_Pin;
  GPIO_InitStruct.Mode = GPIO_MODE_OUTPUT_PP;
  GPIO_InitStruct.Pull = GPIO_NOPULL;
  GPIO_InitStruct.Speed = GPIO_SPEED_FREQ_LOW;
  HAL_GPIO_Init(GPIOA, &GPIO_InitStruct);

  /*Configure GPIO pin : SDMMC1_DETECT_Pin */
  GPIO_InitStruct.Pin = SDMMC1_DETECT_Pin;
  GPIO_InitStruct.Mode = GPIO_MODE_INPUT;
  GPIO_InitStruct.Pull = GPIO_PULLUP;
  HAL_GPIO_Init(SDMMC1_DETECT_GPIO_Port, &GPIO_InitStruct);

}

void StartDefaultTask(void *argument)
{
  /* USER CODE BEGIN 5 */
      player_start();
  /* USER CODE END 5 */
}

void HAL_TIM_PeriodElapsedCallback(TIM_HandleTypeDef *htim)
{
  /* USER CODE BEGIN Callback 0 */
    if (htim->Instance == TIM7) {
       player_tick();
     }
  /* USER CODE END Callback 0 */
  if (htim->Instance == TIM7) {
    HAL_IncTick();
  }
}

void Error_Handler(void)
{
  __disable_irq();
  while (1)
  {
  }
}
